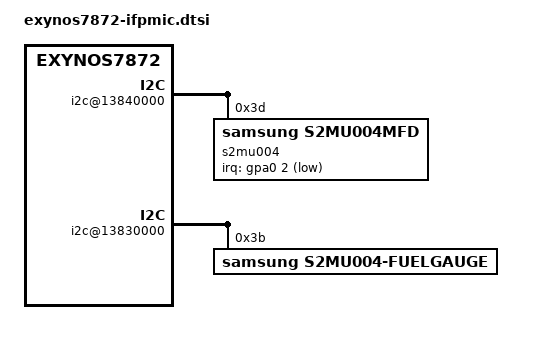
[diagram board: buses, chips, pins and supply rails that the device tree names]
/*
 * SAMSUNG UNIVERSAL5433 board device tree source
 *
 * Copyright (c) 2013 Samsung Electronics Co., Ltd.
 *		http://www.samsung.com
 *
 * This program is free software; you can redistribute it and/or modify
 * it under the terms of the GNU General Public License version 2 as
 * published by the Free Software Foundation.
*/

/ {

	battery_params {
		battery,battery_table1 = <0x8b 0x0b 0x03 0x0b 0x7c 0x0a 0xf4 0x09 0x7f 0x09
			0x0f 0x09 0xa4 0x08 0x3e 0x08 0xc2 0x07 0x7d 0x07
			0x13 0x07 0xcc 0x06 0x99 0x06 0x6f 0x06 0x4d 0x06
			0x31 0x06 0x09 0x06 0xd8 0x05 0x8a 0x05 0x78 0x05
			0x39 0x04 0x74 0x00 0xa0 0x08 0x33 0x08 0xc5 0x07
			0x58 0x07 0xeb 0x06 0x7d 0x06 0x10 0x06 0xa3 0x05
			0x35 0x05 0xc8 0x04 0x5a 0x04 0xed 0x03 0x80 0x03
			0x12 0x03 0xa5 0x02 0x37 0x02 0xca 0x01 0x5d 0x01
			0xef 0x00 0x82 0x00 0x15 0x00 0xde 0x0f>;

		battery,battery_table2 = <0x2c 0x2c 0x2c 0x2b 0x2b 0x01 0x29 0x2c 0x2a 0x2a
			0x2a 0x2a 0x2b 0x2b 0x2b 0x33 0x2e 0x2e 0x31 0x37
			0x45 0x9a>;

		battery,battery_table3 = <229 11 77 11 180 10 30 10 160 9
			43 9 192 8 92 8 224 7 154 7
			62 7 228 6 168 6 124 6 90 6
			64 6 35 6 251 5 198 5 145 5
			69 5 168 1 244 8 132 8 21 8
			165 7 53 7 197 6 85 6 229 5
			118 5 6 5 150 4 38 4 182 3
			70 3 214 2 103 2 247 1 135 1
			23 1 167 0 55 0 200 15>;

		battery,battery_table4 = <69 69 69 69 67 68 66 67 67 65
			66 66 68 69 70 71 73 77 84 94
			112 212>;

		battery,batcap = <0x20 0xD0 0x08 0x34>; /* [0x0F] [0x0E] [0x11] [0x10] */

		battery,soc_arr_val = <11193 10647 10101 9555 9009 8462 7916 7370 6824 6278 5732 5185 4639 4093 3547 3001 2455 1909 1362 816 270 (-276)>;
		battery,ocv_arr_val = <44869 44124 43379 42645 42030 41459 40940 40447 39846 39501 39051 38615 38319 38107 37942 37814 37669 37478 37216 36958 36588 32070>;
	};

	pinctrl@11CB0000 {
		if_pmic_irq: if_pmic_irq {
			samsung,pins = "gpa0-2";
			samsung,pin-pud = <3>;
			samsung,pin-drv = <3>;
	};

		if_pmic_rstb: if_pmic_rstb {
			samsung,pins = "gpa0-4";
			samsung,pin-pud = <3>;
			samsung,pin-pud-pdn = <3>;
			samsung,pin-con-pdn = <3>;
		};
	};

	pinctrl@139B0000 {
		fuel_irq: fuel-irq {
			samsung,pins = "gpg1-5";
			samsung,pin-function = <0>;
			samsung,pin-pud = <0>;
			samsung,pin-drv = <0>;
		};
	};

	i2c@13840000{
		status = "okay";
		s2mu004@3D {
			status = "okay";
			compatible = "samsung,s2mu004mfd";
			reg = <0x3D>;
			pinctrl-names = "default";
			pinctrl-0 = <&if_pmic_irq &if_pmic_rstb>;
			s2mu004,irq-gpio = <&gpa0 2 1>;
			s2mu004,wakeup;
		};
	};

	i2c@13830000{
		status = "okay";
		s2mu004-fuelgauge@3B {
			compatible = "samsung,s2mu004-fuelgauge";
			reg = <0x3B>;
			pinctrl-names = "default";
			pinctrl-0 = <&fuel_irq>;
			fuelgauge,fuel_alert_soc = <1>;
			fuelgauge,capacity_max = <1000>;
			fuelgauge,capacity_max_margin = <70>;
			fuelgauge,capacity_min = <0>;
			fuelgauge,capacity_calculation_type = <12>;
			fuelgauge,capacity_full = <3000>;
			fuelgauge,type_str = "SDI";
			fuelgauge,model_type = <1>;
		};
	};

	s2mu004-charger {
		status = "disable";
		battery,charger_name = "s2mu004-charger";
		battery,chg_gpio_en = <0>;
		battery,chg_polarity_en = <0>;
		battery,chg_gpio_status = <0>;
		battery,chg_polarity_status = <0>;
		battery,chg_float_voltage = <4350>;
		battery,chg_recharge_vcell = <4250>;
		battery,chg_full_vcell = <4300>;
		battery,full_check_type = <2>;
		battery,full_check_type_2nd = <2>;
		battery,input_current_limit = <1800 450 450 1800 500 900 1500 450 1000 450 900 900 900 1900 1800 450 450 400 700 1300 300 1000 1500 450 1650 2100 500 1650 80 1800 1650 1400 1000 1000 700 900 900 900 500 1800 1650 3000>;
		battery,fast_charging_current = <2100 450 450 2100 800 1200 1500 450 1200 450 2100 2100 2100 1600 2100 450 450 400 700 1300 300 1000 1500 450 2400 3500 500 2400 80 1800 1000 1400 450 1000 2100 2100 2100 2100 450 2100 2400 3000>;
		battery,full_check_current_1st = <300 0 0 300 300 300 300 300 300 0 300 300 300 300 300 0 0 300 300 300 300 300 300 0 300 300 300 300 0 300 300 300 0 300 300 300 300 300 300 300 300 300>;
		battery,full_check_current_2nd = <100 0 0 100 100 100 100 100 100 0 100 100 100 100 100 0 0 100 100 100 100 100 100 0 100 100 100 100 0 100 100 100 0 100 100 100 100 100 100 100 100 100>;
	};

};
